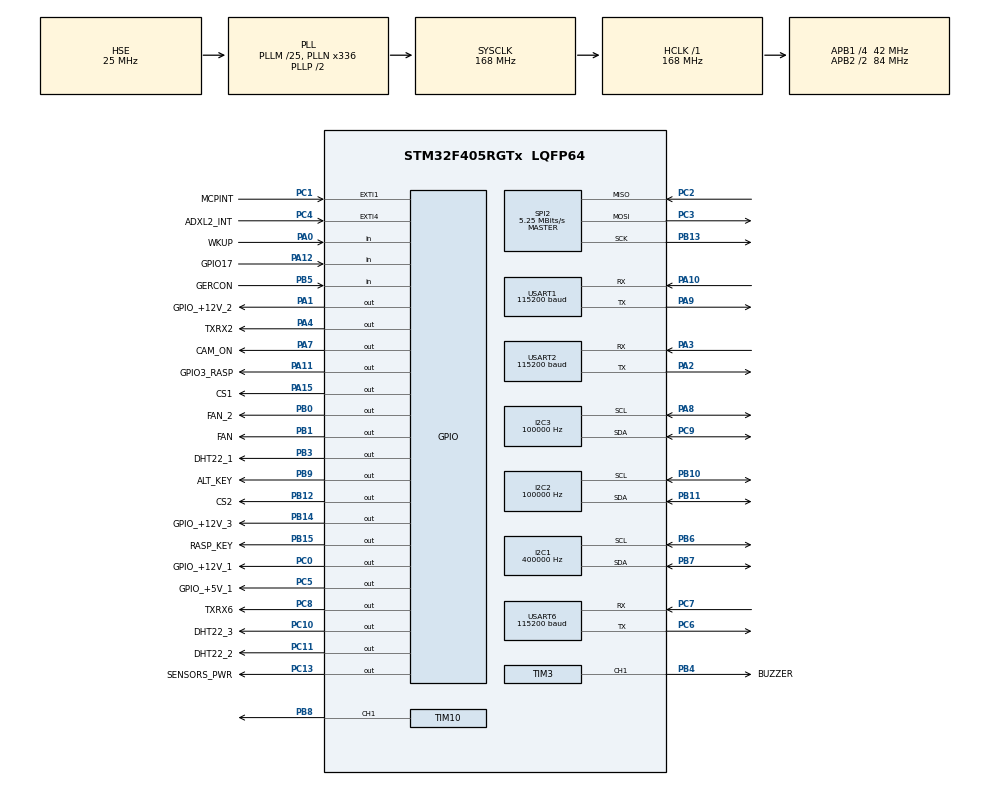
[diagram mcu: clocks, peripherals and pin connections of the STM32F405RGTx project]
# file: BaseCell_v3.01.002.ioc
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Dma.Request0=USART1_RX
Dma.Request1=USART1_TX
Dma.Request2=USART2_RX
Dma.Request3=USART2_TX
Dma.USART1_RX.0.Direction=DMA_PERIPH_TO_MEMORY
Dma.USART1_RX.0.FIFOMode=DMA_FIFOMODE_ENABLE
Dma.USART1_RX.0.FIFOThreshold=DMA_FIFO_THRESHOLD_FULL
Dma.USART1_RX.0.Instance=DMA2_Stream2
Dma.USART1_RX.0.MemBurst=DMA_MBURST_SINGLE
Dma.USART1_RX.0.MemDataAlignment=DMA_MDATAALIGN_BYTE
Dma.USART1_RX.0.MemInc=DMA_MINC_ENABLE
Dma.USART1_RX.0.Mode=DMA_NORMAL
Dma.USART1_RX.0.PeriphBurst=DMA_PBURST_SINGLE
Dma.USART1_RX.0.PeriphDataAlignment=DMA_PDATAALIGN_BYTE
Dma.USART1_RX.0.PeriphInc=DMA_PINC_DISABLE
Dma.USART1_RX.0.Priority=DMA_PRIORITY_LOW
Dma.USART1_TX.1.Direction=DMA_MEMORY_TO_PERIPH
Dma.USART1_TX.1.FIFOMode=DMA_FIFOMODE_ENABLE
Dma.USART1_TX.1.FIFOThreshold=DMA_FIFO_THRESHOLD_FULL
Dma.USART1_TX.1.Instance=DMA2_Stream7
Dma.USART1_TX.1.MemBurst=DMA_MBURST_SINGLE
Dma.USART1_TX.1.MemDataAlignment=DMA_MDATAALIGN_BYTE
Dma.USART1_TX.1.MemInc=DMA_MINC_ENABLE
Dma.USART1_TX.1.Mode=DMA_NORMAL
Dma.USART1_TX.1.PeriphBurst=DMA_PBURST_SINGLE
Dma.USART1_TX.1.PeriphDataAlignment=DMA_PDATAALIGN_BYTE
Dma.USART1_TX.1.PeriphInc=DMA_PINC_DISABLE
Dma.USART1_TX.1.Priority=DMA_PRIORITY_LOW
Dma.USART2_RX.2.Direction=DMA_PERIPH_TO_MEMORY
Dma.USART2_RX.2.FIFOMode=DMA_FIFOMODE_DISABLE
Dma.USART2_RX.2.Instance=DMA1_Stream5
Dma.USART2_RX.2.MemDataAlignment=DMA_MDATAALIGN_BYTE
Dma.USART2_RX.2.MemInc=DMA_MINC_ENABLE
Dma.USART2_RX.2.Mode=DMA_NORMAL
Dma.USART2_RX.2.PeriphDataAlignment=DMA_PDATAALIGN_BYTE
Dma.USART2_RX.2.PeriphInc=DMA_PINC_DISABLE
Dma.USART2_RX.2.Priority=DMA_PRIORITY_MEDIUM
Dma.USART2_TX.3.Direction=DMA_MEMORY_TO_PERIPH
Dma.USART2_TX.3.FIFOMode=DMA_FIFOMODE_ENABLE
Dma.USART2_TX.3.FIFOThreshold=DMA_FIFO_THRESHOLD_FULL
Dma.USART2_TX.3.Instance=DMA1_Stream6
Dma.USART2_TX.3.MemBurst=DMA_MBURST_SINGLE
Dma.USART2_TX.3.MemDataAlignment=DMA_MDATAALIGN_BYTE
Dma.USART2_TX.3.MemInc=DMA_MINC_ENABLE
Dma.USART2_TX.3.Mode=DMA_NORMAL
Dma.USART2_TX.3.PeriphBurst=DMA_PBURST_SINGLE
Dma.USART2_TX.3.PeriphDataAlignment=DMA_PDATAALIGN_BYTE
Dma.USART2_TX.3.PeriphInc=DMA_PINC_DISABLE
Dma.USART2_TX.3.Priority=DMA_PRIORITY_MEDIUM
FREERTOS.HEAP_NUMBER=4
FREERTOS.INCLUDE_eTaskGetState=0
FREERTOS.INCLUDE_pcTaskGetTaskName=0
FREERTOS.INCLUDE_uxTaskGetStackHighWaterMark=0
FREERTOS.INCLUDE_uxTaskPriorityGet=1
FREERTOS.INCLUDE_vTaskCleanUpResources=0
FREERTOS.INCLUDE_vTaskDelay=1
FREERTOS.INCLUDE_vTaskDelayUntil=0
FREERTOS.INCLUDE_vTaskDelete=1
FREERTOS.INCLUDE_vTaskPrioritySet=1
FREERTOS.INCLUDE_vTaskSuspend=1
FREERTOS.INCLUDE_xEventGroupSetBitFromISR=0
FREERTOS.INCLUDE_xQueueGetMutexHolder=0
FREERTOS.INCLUDE_xSemaphoreGetMutexHolder=0
FREERTOS.INCLUDE_xTaskAbortDelay=0
FREERTOS.INCLUDE_xTaskGetCurrentTaskHandle=0
FREERTOS.INCLUDE_xTaskGetHandle=0
FREERTOS.INCLUDE_xTaskResumeFromISR=1
FREERTOS.MEMORY_ALLOCATION=2
FREERTOS.Mutexes01=I2C2Mutex,Dynamic,NULL;spiMutex,Dynamic,NULL
FREERTOS.Queues01=onOffQueue,8,uint16_t,0,Dynamic,NULL,NULL;watchDogQ,4,uint16_t,0,Dynamic,NULL,NULL
FREERTOS.Tasks01=defaultTask,0,256,StartDefaultTask,Default,NULL,Dynamic,NULL,NULL;lightMeter,0,256,lightMeterTask,As weak,NULL,Dynamic,NULL,NULL;accel,0,256,accelTask,Default,NULL,Dynamic,NULL,NULL;tempMeas,0,256,tempMeasTask,Default,NULL,Dynamic,NULL,NULL;uartComm,0,256,uartCommTask,As weak,NULL,Dynamic,NULL,NULL;dimmer,0,256,dimmerTask,As external,NULL,Dynamic,NULL,NULL;canRx,0,256,canRxTask,As external,NULL,Dynamic,NULL,NULL;canTx,0,256,canTxTask,As external,NULL,Dynamic,NULL,NULL
FREERTOS.configCHECK_FOR_STACK_OVERFLOW=0
FREERTOS.configENABLE_BACKWARD_COMPATIBILITY=1
FREERTOS.configGENERATE_RUN_TIME_STATS=1
FREERTOS.configIDLE_SHOULD_YIELD=1
FREERTOS.configLIBRARY_LOWEST_INTERRUPT_PRIORITY=15
FREERTOS.configLIBRARY_MAX_SYSCALL_INTERRUPT_PRIORITY=5
FREERTOS.configMAX_CO_ROUTINE_PRIORITIES=2
FREERTOS.configMAX_PRIORITIES=7
FREERTOS.configMAX_TASK_NAME_LEN=16
FREERTOS.configMINIMAL_STACK_SIZE=128
FREERTOS.configQUEUE_REGISTRY_SIZE=8
FREERTOS.configRECORD_STACK_HIGH_ADDRESS=0
FREERTOS.configTICK_RATE_HZ=1000
FREERTOS.configTOTAL_HEAP_SIZE=32768
FREERTOS.configUSE_APPLICATION_TASK_TAG=0
FREERTOS.configUSE_COUNTING_SEMAPHORES=0
FREERTOS.configUSE_CO_ROUTINES=0
FREERTOS.configUSE_DAEMON_TASK_STARTUP_HOOK=0
FREERTOS.configUSE_IDLE_HOOK=0
FREERTOS.configUSE_MALLOC_FAILED_HOOK=0
FREERTOS.configUSE_MUTEXES=1
FREERTOS.configUSE_NEWLIB_REENTRANT=1
FREERTOS.configUSE_PREEMPTION=1
FREERTOS.configUSE_RECURSIVE_MUTEXES=0
FREERTOS.configUSE_STATS_FORMATTING_FUNCTIONS=1
FREERTOS.configUSE_TASK_NOTIFICATIONS=1
FREERTOS.configUSE_TICKLESS_IDLE=0
FREERTOS.configUSE_TICK_HOOK=0
FREERTOS.configUSE_TIMERS=0
FREERTOS.configUSE_TRACE_FACILITY=1
FREERTOS.copyHeapFile=1
I2C1.AddressingMode=I2C_ADDRESSINGMODE_7BIT
I2C1.ClockSpeed=400000
I2C1.DualAddressMode=I2C_DUALADDRESS_DISABLE
I2C1.GeneralCallMode=I2C_GENERALCALL_DISABLE
I2C1.I2C_Mode=I2C_Fast
I2C1.NoStretchMode=I2C_NOSTRETCH_DISABLE
I2C1.OwnAddress=0
I2C2.AddressingMode=I2C_ADDRESSINGMODE_7BIT
I2C2.ClockSpeed=100000
I2C2.DualAddressMode=I2C_DUALADDRESS_DISABLE
I2C2.GeneralCallMode=I2C_GENERALCALL_DISABLE
I2C2.I2C_Mode=I2C_Standard
I2C2.NoStretchMode=I2C_NOSTRETCH_DISABLE
I2C2.OwnAddress=0
I2C3.AddressingMode=I2C_ADDRESSINGMODE_7BIT
I2C3.ClockSpeed=100000
I2C3.DualAddressMode=I2C_DUALADDRESS_DISABLE
I2C3.GeneralCallMode=I2C_GENERALCALL_DISABLE
I2C3.I2C_Mode=I2C_Standard
I2C3.NoStretchMode=I2C_NOSTRETCH_DISABLE
I2C3.OwnAddress=0
Mcu.Family=STM32F4
Mcu.Name=STM32F405RGTx
Mcu.Package=LQFP64
NVIC.DMA1_Stream5_IRQn=true\:5\:0\:false\:false\:true\:true\:false\:true\:true
NVIC.DMA1_Stream6_IRQn=true\:5\:0\:false\:false\:true\:true\:false\:true\:true
NVIC.DMA2_Stream2_IRQn=true\:5\:0\:false\:false\:true\:true\:false\:true\:true
NVIC.DMA2_Stream7_IRQn=true\:5\:0\:false\:false\:true\:true\:false\:true\:true
NVIC.EXTI1_IRQn=true\:5\:0\:false\:false\:true\:true\:true\:true\:true
NVIC.EXTI4_IRQn=true\:5\:0\:false\:false\:true\:true\:true\:true\:true
NVIC.I2C2_ER_IRQn=true\:5\:0\:false\:false\:true\:true\:true\:true\:true
NVIC.PriorityGroup=NVIC_PRIORITYGROUP_4
NVIC.TIM1_TRG_COM_TIM11_IRQn=true\:5\:0\:false\:false\:true\:true\:true\:true\:true
NVIC.TIM1_UP_TIM10_IRQn=true\:5\:0\:false\:false\:true\:true\:true\:true\:true
NVIC.TIM6_DAC_IRQn=true\:15\:0\:false\:false\:true\:false\:true\:true\:true
NVIC.TIM7_IRQn=true\:5\:0\:false\:false\:true\:true\:true\:true\:true
NVIC.TIM8_TRG_COM_TIM14_IRQn=true\:5\:0\:false\:false\:true\:true\:true\:true\:true
NVIC.TIM8_UP_TIM13_IRQn=true\:5\:0\:false\:false\:true\:true\:true\:true\:true
NVIC.TimeBase=TIM6_DAC_IRQn
NVIC.TimeBaseIP=TIM6
NVIC.USART1_IRQn=true\:5\:0\:false\:false\:true\:true\:true\:true\:true
NVIC.USART2_IRQn=true\:5\:0\:false\:false\:true\:true\:true\:true\:true
NVIC.USART6_IRQn=true\:5\:0\:false\:false\:true\:true\:true\:true\:true
PA0-WKUP.GPIO_Label=WKUP
PA0-WKUP.Signal=GPIO_Input
PA1.GPIO_Label=GPIO_+12V_2
PA1.Signal=GPIO_Output
PA10.Mode=Asynchronous
PA10.Signal=USART1_RX
PA11.GPIO_Label=GPIO3_RASP
PA11.PinState=GPIO_PIN_SET
PA11.Signal=GPIO_Output
PA12.GPIO_Label=GPIO17
PA12.Signal=GPIO_Input
PA13.Mode=Serial_Wire
PA13.Signal=SYS_JTMS-SWDIO
PA14.Mode=Serial_Wire
PA14.Signal=SYS_JTCK-SWCLK
PA15.GPIO_Label=CS1
PA15.GPIO_Speed=GPIO_SPEED_FREQ_VERY_HIGH
PA15.PinState=GPIO_PIN_SET
PA15.Signal=GPIO_Output
PA2.Mode=Asynchronous
PA2.Signal=USART2_TX
PA3.Mode=Asynchronous
PA3.Signal=USART2_RX
PA4.GPIO_Label=TXRX2
PA4.Signal=GPIO_Output
PA7.GPIO_Label=CAM_ON
PA7.Signal=GPIO_Output
PA8.GPIO_Pu=GPIO_PULLUP
PA8.Mode=I2C
PA8.Signal=I2C3_SCL
PA9.Mode=Asynchronous
PA9.Signal=USART1_TX
PB0.GPIO_Label=FAN_2
PB0.Signal=GPIO_Output
PB1.GPIO_Label=FAN
PB1.Signal=GPIO_Output
PB10.GPIO_Pu=GPIO_PULLUP
PB10.Mode=I2C
PB10.Signal=I2C2_SCL
PB11.GPIO_Pu=GPIO_PULLUP
PB11.Mode=I2C
PB11.Signal=I2C2_SDA
PB12.GPIO_Label=CS2
PB12.GPIO_Speed=GPIO_SPEED_FREQ_VERY_HIGH
PB12.PinState=GPIO_PIN_SET
PB12.Signal=GPIO_Output
PB13.Mode=Full_Duplex_Master
PB13.Signal=SPI2_SCK
PB14.GPIO_Label=GPIO_+12V_3
PB14.Signal=GPIO_Output
PB15.GPIO_Label=RASP_KEY
PB15.Signal=GPIO_Output
PB3.GPIO_Label=DHT22_1
PB3.Signal=GPIO_Output
PB4.GPIO_Label=BUZZER
PB4.GPIO_Speed=GPIO_SPEED_FREQ_HIGH
PB4.Signal=S_TIM3_CH1
PB5.GPIO_Label=GERCON
PB5.Signal=GPIO_Input
PB6.GPIO_Pu=GPIO_PULLUP
PB6.Mode=I2C
PB6.Signal=I2C1_SCL
PB7.GPIO_Pu=GPIO_PULLUP
PB7.Mode=I2C
PB7.Signal=I2C1_SDA
PB8.Signal=S_TIM10_CH1
PB9.GPIO_Label=ALT_KEY
PB9.Signal=GPIO_Output
PC0.GPIO_Label=GPIO_+12V_1
PC0.Signal=GPIO_Output
PC1.GPIO_Label=MCPINT
PC1.GPIO_ModeDefaultEXTI=GPIO_MODE_IT_FALLING
PC1.GPIO_PuPd=GPIO_PULLUP
PC1.Signal=GPXTI1
PC10.GPIO_Label=DHT22_3
PC10.Signal=GPIO_Output
PC11.GPIO_Label=DHT22_2
PC11.Signal=GPIO_Output
PC13-ANTI_TAMP.GPIO_Label=SENSORS_PWR
PC13-ANTI_TAMP.Signal=GPIO_Output
PC2.Mode=Full_Duplex_Master
PC2.Signal=SPI2_MISO
PC3.Mode=Full_Duplex_Master
PC3.Signal=SPI2_MOSI
PC4.GPIO_Label=ADXL2_INT
PC4.Signal=GPXTI4
PC5.GPIO_Label=GPIO_+5V_1
PC5.Signal=GPIO_Output
PC6.Mode=Asynchronous
PC6.Signal=USART6_TX
PC7.Mode=Asynchronous
PC7.Signal=USART6_RX
PC8.GPIO_Label=TXRX6
PC8.Signal=GPIO_Output
PC9.GPIO_Pu=GPIO_PULLUP
PC9.Mode=I2C
PC9.Signal=I2C3_SDA
PH0-OSC_IN.Mode=HSE-External-Oscillator
PH0-OSC_IN.Signal=RCC_OSC_IN
PH1-OSC_OUT.Mode=HSE-External-Oscillator
PH1-OSC_OUT.Signal=RCC_OSC_OUT
ProjectManager.HeapSize=0x2000
ProjectManager.StackSize=0x4000
ProjectManager.TargetToolchain=STM32CubeIDE
RCC.48MHZClocksFreq_Value=84000000
RCC.AHBFreq_Value=168000000
RCC.APB1CLKDivider=RCC_HCLK_DIV4
RCC.APB1Freq_Value=42000000
RCC.APB1TimFreq_Value=84000000
RCC.APB2CLKDivider=RCC_HCLK_DIV2
RCC.APB2Freq_Value=84000000
RCC.APB2TimFreq_Value=168000000
RCC.CortexFreq_Value=168000000
RCC.FLatency=FLASH_LATENCY_5
RCC.HCLKFreq_Value=168000000
RCC.HSE_VALUE=25000000
RCC.HSI_VALUE=16000000
RCC.LSE_VALUE=32768
RCC.PLLM=25
RCC.PLLN=336
RCC.PLLSourceVirtual=RCC_PLLSOURCE_HSE
RCC.SYSCLKFreq_VALUE=168000000
RCC.SYSCLKSource=RCC_SYSCLKSOURCE_PLLCLK
RCC.VCOOutputFreq_Value=336000000
SH.S_TIM10_CH1.0=TIM10_CH1,PWM Generation1 CH1
SH.S_TIM3_CH1.0=TIM3_CH1,PWM Generation1 CH1
SPI2.BaudRatePrescaler=SPI_BAUDRATEPRESCALER_8
SPI2.CalculateBaudRate=5.25 MBits/s
SPI2.Direction=SPI_DIRECTION_2LINES
SPI2.Mode=SPI_MODE_MASTER
SPI2.VirtualType=VM_MASTER
TIM10.Channel=TIM_CHANNEL_1
TIM10.Period=999
TIM10.Prescaler=167
TIM11.AutoReloadPreload=TIM_AUTORELOAD_PRELOAD_DISABLE
TIM11.ClockDivision=TIM_CLOCKDIVISION_DIV1
TIM11.CounterMode=TIM_COUNTERMODE_UP
TIM11.Period=999
TIM11.Prescaler=167
TIM13.Period=19999
TIM13.Prescaler=167
TIM14.Period=99
TIM14.Prescaler=83
TIM3.AutoReloadPreload=TIM_AUTORELOAD_PRELOAD_DISABLE
TIM3.Channel-PWM\ Generation1\ CH1=TIM_CHANNEL_1
TIM3.ClockDivision=TIM_CLOCKDIVISION_DIV1
TIM3.CounterMode=TIM_COUNTERMODE_UP
TIM3.OC1Preload_PWM=ENABLE
TIM3.OCFastMode_PWM-PWM\ Generation1\ CH1=TIM_OCFAST_DISABLE
TIM3.OCMode_PWM-PWM\ Generation1\ CH1=TIM_OCMODE_PWM1
TIM3.OCPolarity_1=TIM_OCPOLARITY_HIGH
TIM3.Period=499
TIM3.Prescaler=83
TIM3.Pulse-PWM\ Generation1\ CH1=124
TIM3.TIM_MasterOutputTrigger=TIM_TRGO_RESET
TIM3.TIM_MasterSlaveMode=TIM_MASTERSLAVEMODE_DISABLE
TIM7.AutoReloadPreload=TIM_AUTORELOAD_PRELOAD_DISABLE
TIM7.CounterMode=TIM_COUNTERMODE_UP
TIM7.Period=65535
TIM7.Prescaler=16799
TIM7.TIM_MasterOutputTrigger=TIM_TRGO_RESET
TIM8.Period=1999
TIM8.Prescaler=16799
USART1.BaudRate=115200
USART1.Mode=MODE_TX_RX
USART1.OverSampling=UART_OVERSAMPLING_16
USART1.Parity=PARITY_NONE
USART1.StopBits=STOPBITS_1
USART1.VirtualMode=VM_ASYNC
USART1.WordLength=WORDLENGTH_8B
USART2.BaudRate=115200
USART2.Mode=MODE_TX_RX
USART2.OverSampling=UART_OVERSAMPLING_16
USART2.Parity=PARITY_NONE
USART2.StopBits=STOPBITS_1
USART2.VirtualMode=VM_ASYNC
USART2.WordLength=WORDLENGTH_8B
USART6.BaudRate=115200
USART6.Mode=MODE_TX_RX
USART6.OverSampling=UART_OVERSAMPLING_16
USART6.Parity=PARITY_NONE
USART6.StopBits=STOPBITS_1
USART6.VirtualMode=VM_ASYNC
USART6.WordLength=WORDLENGTH_8B
VP_FREERTOS_VS_CMSIS_V1.Mode=CMSIS_V1
VP_SYS_VS_tim6.Mode=TIM6
VP_TIM10_VS_ClockSourceINT.Mode=Enable_Timer
VP_TIM11_VS_ClockSourceINT.Mode=Enable_Timer
VP_TIM13_VS_ClockSourceINT.Mode=Enable_Timer
VP_TIM14_VS_ClockSourceINT.Mode=Enable_Timer
VP_TIM3_VS_ClockSourceINT.Mode=Internal
VP_TIM7_VS_ClockSourceINT.Mode=Enable_Timer
VP_TIM8_VS_ClockSourceINT.Mode=Internal
board=custom

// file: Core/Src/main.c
/* USER CODE BEGIN Header */
/**
  ******************************************************************************
  * @file           : main.c
  * @brief          : Main program body
  ******************************************************************************
  * @attention
  *
  * <h2><center>&copy; Copyright (c) 2021 STMicroelectronics.
  * All rights reserved.</center></h2>
  *
  * This software component is licensed by ST under Ultimate Liberty license
  * SLA0044, the "License"; You may not use this file except in compliance with
  * the License. You may obtain a copy of the License at:
  *                             www.st.com/SLA0044
  *
  ******************************************************************************
  */
/* USER CODE END Header */
#include "main.h"
#include "cmsis_os.h"

/* USER CODE BEGIN Includes */
#include "stm32f4xx_hal.h"
#include "string.h"
#include "adxl345.h"
#include "tla2024.h"
#include "dht22.h"
#include "apds9960.h"
#include "usart.h"
#include "utilites.h"
#include "eeprom.h"
#include "dimmer.h"
#include "CANSPI.h"
/* USER CODE END Includes */

/* USER CODE BEGIN PD */
#define CV_EXT_INTERRUPT_ID 	0x05
#define TIM11_DELAY_ID			0x06

#define RASP_OFF_COUNTER		500
#define RASP_SHTDN_DELAY		45000

#define TEMPERATURE				400
#define TEMP_HYSTERESE			20
#define TEMP_SENS_NORM			1
#define TEMP_SENSOR_FAIL		0
/* USER CODE END PD */

 I2C_HandleTypeDef hi2c1;
I2C_HandleTypeDef hi2c2;
I2C_HandleTypeDef hi2c3;

SPI_HandleTypeDef hspi2;

TIM_HandleTypeDef htim3;
TIM_HandleTypeDef htim7;
TIM_HandleTypeDef htim8;
TIM_HandleTypeDef htim10;
TIM_HandleTypeDef htim11;
TIM_HandleTypeDef htim13;
TIM_HandleTypeDef htim14;

UART_HandleTypeDef huart1;
UART_HandleTypeDef huart2;
UART_HandleTypeDef huart6;
DMA_HandleTypeDef hdma_usart1_rx;
DMA_HandleTypeDef hdma_usart1_tx;
DMA_HandleTypeDef hdma_usart2_rx;
DMA_HandleTypeDef hdma_usart2_tx;

osThreadId defaultTaskHandle;
osThreadId lightMeterHandle;
osThreadId accelHandle;
osThreadId tempMeasHandle;
osThreadId uartCommHandle;
osThreadId dimmerHandle;
osThreadId canRxHandle;
osThreadId canTxHandle;
osMessageQId onOffQueueHandle;
osMessageQId watchDogQHandle;
osMutexId I2C2MutexHandle;
osMutexId spiMutexHandle;
/* USER CODE BEGIN PV */

QueueHandle_t qSensorsHandle;
uint8_t qSensorsBuffer[ MAIL_SIZE * sizeof( sensorsData ) ];
StaticQueue_t qSensorsQueueBuffer;

uint16_t tickCounter = 0;
uint8_t currentVoltageRxBuf [CV_RX_BUF_SIZE];
uint8_t raspRxBuf [RASP_RX_BUF_SIZE];
uint8_t fanAutoFlag = 0;
int16_t accelX = 0;
int16_t accelY = 0;
int16_t accelZ = 0;

uint8_t intSource = 0;
float Xresult;
float Yresult;
float Zresult;

uint8_t shutdownFlag = 0;
uint32_t shutdownCounter = 0;
uint16_t gerconCounter = 0;
uint16_t cvRequestCounter = 0;
uint8_t gerconState = 0;

uint32_t raspOffCounter = 0;
uint16_t stateChangeCounter = 0;
uint8_t raspOffState = 0;

uint16_t wakeUpPinCounter = 0;
uint8_t wakeUpFlag = 0;

uint32_t secondCounter = 0;

uint16_t pulseDuration = 0;
const uint8_t cvTimeoutResponse[8] = {0xAA, 0x0F, 0x08, 0x11, 0x01, 0, 0, 0x55};

extern uint8_t engineSwitchFlag;
extern uint16_t onBoardVoltage;
extern uint8_t engineState;
extern uint8_t misStatusByte0;
extern uint8_t misStatusByte1;
extern uint8_t cvStatusByteExtern;
extern uint8_t breaksStateTelem;
extern uint8_t queueStatusByte;
extern uint8_t queueStatusByte1;
extern uint8_t cmdTempBuf[16];
//extern UBaseType_t mailInQueue;

extern uint8_t destTempBuf[16];

uint16_t VirtAddVarTab[NB_OF_VAR];
uint8_t tempSensorState = 0;
uint8_t tempSensorState1 = 0;
uint8_t sensorsOnFlag = 1;

volatile unsigned long ulHighFrequencyTimerTicks;

int16_t debugTemp0;
int16_t debugTemp1;
int16_t debugTemp2;

__IO int32_t osMailFreeCounter = 0;
__IO uint32_t queueErrorCnt = 0;

static volatile sensorsData xSensor, xSensor1;
static volatile sensorsData *sensor = &xSensor;
static volatile sensorsData *sensor1 = &xSensor1;

uint8_t resetFlag = 0;
uint8_t gpio17State = 0;
uint8_t turnOffBreaksFlag = 0;

volatile uint8_t timeOutFlag = 0;
volatile uint32_t timeoutCnt = 0;
volatile uint8_t raspRestartFlag = 0;

static volatile uint8_t cvCounter = 0;
uint32_t timeOutCounter = 0;
uint32_t uartErrorCounter = 0;

float pwmValue;
uint16_t pwm_Value;
uint16_t targetValue;
BH1750_device_t* monitor;
uint32_t i2c2ErrorCode = 0;
/* USER CODE END PV */

void SystemClock_Config(void);
static void MX_GPIO_Init(void);
static void MX_DMA_Init(void);
static void MX_I2C1_Init(void);
static void MX_I2C2_Init(void);
static void MX_I2C3_Init(void);
static void MX_TIM3_Init(void);
static void MX_USART1_UART_Init(void);
static void MX_USART2_UART_Init(void);
static void MX_USART6_UART_Init(void);
static void MX_TIM7_Init(void);
static void MX_TIM11_Init(void);
static void MX_TIM13_Init(void);
static void MX_TIM14_Init(void);
static void MX_TIM10_Init(void);
static void MX_TIM8_Init(void);
static void MX_SPI2_Init(void);
void StartDefaultTask(void const * argument);
void lightMeterTask(void const * argument);
void accelTask(void const * argument);
void tempMeasTask(void const * argument);
void uartCommTask(void const * argument);
extern void dimmerTask(void const * argument);
extern void canRxTask(void const * argument);
extern void canTxTask(void const * argument);

int main(void)
{

  /* MCU Configuration--------------------------------------------------------*/

  /* Reset of all peripherals, Initializes the Flash interface and the Systick. */
  HAL_Init();

  /* Configure the system clock */
  SystemClock_Config();

  /* Initialize all configured peripherals */
  MX_GPIO_Init();
  MX_DMA_Init();
  MX_I2C1_Init();
  MX_I2C2_Init();
  MX_I2C3_Init();
  MX_TIM3_Init();
  MX_USART1_UART_Init();
  MX_USART2_UART_Init();
  MX_USART6_UART_Init();
  MX_TIM7_Init();
  MX_TIM11_Init();
  MX_TIM13_Init();
  MX_TIM14_Init();
  MX_TIM10_Init();
  MX_TIM8_Init();
  MX_SPI2_Init();
  /* USER CODE BEGIN 2 */
  HAL_GPIO_WritePin(TXRX6_GPIO_Port, TXRX6_Pin, RESET);

  HAL_GPIO_WritePin(SENSORS_PWR_GPIO_Port, SENSORS_PWR_Pin, SET);

  HAL_TIM_Base_Start_IT(&htim11);

	TLA2024_Init();
	HAL_TIM_Base_Stop_IT(&htim13);
	HAL_TIM_Base_Stop_IT(&htim10);
	monitor = BH1750_init_dev_struct(&hi2c3, "monitor", true);
	BH1750_init_dev(monitor);
	HAL_TIM_PWM_Start(&htim10, TIM_CHANNEL_1);

  /* USER CODE END 2 */

  /* Create the mutex(es) */
  /* definition and creation of I2C2Mutex */
  osMutexDef(I2C2Mutex);
  I2C2MutexHandle = osMutexCreate(osMutex(I2C2Mutex));

  /* definition and creation of spiMutex */
  osMutexDef(spiMutex);
  spiMutexHandle = osMutexCreate(osMutex(spiMutex));

  /* Create the queue(s) */
  /* definition and creation of onOffQueue */
  osMessageQDef(onOffQueue, 8, uint16_t);
  onOffQueueHandle = osMessageCreate(osMessageQ(onOffQueue), NULL);

  /* definition and creation of watchDogQ */
  osMessageQDef(watchDogQ, 4, uint16_t);
  watchDogQHandle = osMessageCreate(osMessageQ(watchDogQ), NULL);

  /* USER CODE BEGIN RTOS_QUEUES */
  /* add queues, ... */
  qSensorsHandle = xQueueCreateStatic(MAIL_SIZE, sizeof (sensorsData), &qSensorsBuffer[0], &qSensorsQueueBuffer);

  /* USER CODE END RTOS_QUEUES */

  /* Create the thread(s) */
  /* definition and creation of defaultTask */
  osThreadDef(defaultTask, StartDefaultTask, osPriorityNormal, 0, 256);
  defaultTaskHandle = osThreadCreate(osThread(defaultTask), NULL);

  /* definition and creation of lightMeter */
  osThreadDef(lightMeter, lightMeterTask, osPriorityNormal, 0, 256);
  lightMeterHandle = osThreadCreate(osThread(lightMeter), NULL);

  /* definition and creation of accel */
  osThreadDef(accel, accelTask, osPriorityNormal, 0, 256);
  accelHandle = osThreadCreate(osThread(accel), NULL);

  /* definition and creation of tempMeas */
  osThreadDef(tempMeas, tempMeasTask, osPriorityNormal, 0, 256);
  tempMeasHandle = osThreadCreate(osThread(tempMeas), NULL);

  /* definition and creation of uartComm */
  osThreadDef(uartComm, uartCommTask, osPriorityNormal, 0, 256);
  uartCommHandle = osThreadCreate(osThread(uartComm), NULL);

  /* definition and creation of dimmer */
  osThreadDef(dimmer, dimmerTask, osPriorityNormal, 0, 256);
  dimmerHandle = osThreadCreate(osThread(dimmer), NULL);

  /* definition and creation of canRx */
  osThreadDef(canRx, canRxTask, osPriorityNormal, 0, 256);
  canRxHandle = osThreadCreate(osThread(canRx), NULL);

  /* definition and creation of canTx */
  osThreadDef(canTx, canTxTask, osPriorityNormal, 0, 256);
  canTxHandle = osThreadCreate(osThread(canTx), NULL);

  /* Start scheduler */
  osKernelStart();

  /* We should never get here as control is now taken by the scheduler */
  /* Infinite loop */
  while (1)
  {

  }
}

void SystemClock_Config(void)
{
  RCC_OscInitTypeDef RCC_OscInitStruct = {0};
  RCC_ClkInitTypeDef RCC_ClkInitStruct = {0};

  /** Configure the main internal regulator output voltage
  */
  __HAL_RCC_PWR_CLK_ENABLE();
  __HAL_PWR_VOLTAGESCALING_CONFIG(PWR_REGULATOR_VOLTAGE_SCALE1);

  /** Initializes the RCC Oscillators according to the specified parameters
  * in the RCC_OscInitTypeDef structure.
  */
  RCC_OscInitStruct.OscillatorType = RCC_OSCILLATORTYPE_HSE;
  RCC_OscInitStruct.HSEState = RCC_HSE_ON;
  RCC_OscInitStruct.PLL.PLLState = RCC_PLL_ON;
  RCC_OscInitStruct.PLL.PLLSource = RCC_PLLSOURCE_HSE;
  RCC_OscInitStruct.PLL.PLLM = 25;
  RCC_OscInitStruct.PLL.PLLN = 336;
  RCC_OscInitStruct.PLL.PLLP = RCC_PLLP_DIV2;
  RCC_OscInitStruct.PLL.PLLQ = 4;
  if (HAL_RCC_OscConfig(&RCC_OscInitStruct) != HAL_OK)
  {
    Error_Handler();
  }

  /** Initializes the CPU, AHB and APB buses clocks
  */
  RCC_ClkInitStruct.ClockType = RCC_CLOCKTYPE_HCLK|RCC_CLOCKTYPE_SYSCLK
                              |RCC_CLOCKTYPE_PCLK1|RCC_CLOCKTYPE_PCLK2;
  RCC_ClkInitStruct.SYSCLKSource = RCC_SYSCLKSOURCE_PLLCLK;
  RCC_ClkInitStruct.AHBCLKDivider = RCC_SYSCLK_DIV1;
  RCC_ClkInitStruct.APB1CLKDivider = RCC_HCLK_DIV4;
  RCC_ClkInitStruct.APB2CLKDivider = RCC_HCLK_DIV2;

  if (HAL_RCC_ClockConfig(&RCC_ClkInitStruct, FLASH_LATENCY_5) != HAL_OK)
  {
    Error_Handler();
  }
}

static void MX_I2C1_Init(void)
{

  hi2c1.Instance = I2C1;
  hi2c1.Init.ClockSpeed = 400000;
  hi2c1.Init.DutyCycle = I2C_DUTYCYCLE_2;
  hi2c1.Init.OwnAddress1 = 0;
  hi2c1.Init.AddressingMode = I2C_ADDRESSINGMODE_7BIT;
  hi2c1.Init.DualAddressMode = I2C_DUALADDRESS_DISABLE;
  hi2c1.Init.OwnAddress2 = 0;
  hi2c1.Init.GeneralCallMode = I2C_GENERALCALL_DISABLE;
  hi2c1.Init.NoStretchMode = I2C_NOSTRETCH_DISABLE;
  if (HAL_I2C_Init(&hi2c1) != HAL_OK)
  {
    Error_Handler();
  }

}

static void MX_I2C2_Init(void)
{

  hi2c2.Instance = I2C2;
  hi2c2.Init.ClockSpeed = 100000;
  hi2c2.Init.DutyCycle = I2C_DUTYCYCLE_2;
  hi2c2.Init.OwnAddress1 = 0;
  hi2c2.Init.AddressingMode = I2C_ADDRESSINGMODE_7BIT;
  hi2c2.Init.DualAddressMode = I2C_DUALADDRESS_DISABLE;
  hi2c2.Init.OwnAddress2 = 0;
  hi2c2.Init.GeneralCallMode = I2C_GENERALCALL_DISABLE;
  hi2c2.Init.NoStretchMode = I2C_NOSTRETCH_DISABLE;
  if (HAL_I2C_Init(&hi2c2) != HAL_OK)
  {
    Error_Handler();
  }

}

static void MX_I2C3_Init(void)
{

  hi2c3.Instance = I2C3;
  hi2c3.Init.ClockSpeed = 100000;
  hi2c3.Init.DutyCycle = I2C_DUTYCYCLE_2;
  hi2c3.Init.OwnAddress1 = 0;
  hi2c3.Init.AddressingMode = I2C_ADDRESSINGMODE_7BIT;
  hi2c3.Init.DualAddressMode = I2C_DUALADDRESS_DISABLE;
  hi2c3.Init.OwnAddress2 = 0;
  hi2c3.Init.GeneralCallMode = I2C_GENERALCALL_DISABLE;
  hi2c3.Init.NoStretchMode = I2C_NOSTRETCH_DISABLE;
  if (HAL_I2C_Init(&hi2c3) != HAL_OK)
  {
    Error_Handler();
  }

}

static void MX_SPI2_Init(void)
{

  /* SPI2 parameter configuration*/
  hspi2.Instance = SPI2;
  hspi2.Init.Mode = SPI_MODE_MASTER;
  hspi2.Init.Direction = SPI_DIRECTION_2LINES;
  hspi2.Init.DataSize = SPI_DATASIZE_8BIT;
  hspi2.Init.CLKPolarity = SPI_POLARITY_LOW;
  hspi2.Init.CLKPhase = SPI_PHASE_1EDGE;
  hspi2.Init.NSS = SPI_NSS_SOFT;
  hspi2.Init.BaudRatePrescaler = SPI_BAUDRATEPRESCALER_8;
  hspi2.Init.FirstBit = SPI_FIRSTBIT_MSB;
  hspi2.Init.TIMode = SPI_TIMODE_DISABLE;
  hspi2.Init.CRCCalculation = SPI_CRCCALCULATION_DISABLE;
  hspi2.Init.CRCPolynomial = 10;
  if (HAL_SPI_Init(&hspi2) != HAL_OK)
  {
    Error_Handler();
  }

}

static void MX_TIM3_Init(void)
{

  TIM_ClockConfigTypeDef sClockSourceConfig = {0};
  TIM_MasterConfigTypeDef sMasterConfig = {0};
  TIM_OC_InitTypeDef sConfigOC = {0};

  htim3.Instance = TIM3;
  htim3.Init.Prescaler = 83;
  htim3.Init.CounterMode = TIM_COUNTERMODE_UP;
  htim3.Init.Period = 499;
  htim3.Init.ClockDivision = TIM_CLOCKDIVISION_DIV1;
  htim3.Init.AutoReloadPreload = TIM_AUTORELOAD_PRELOAD_DISABLE;
  if (HAL_TIM_Base_Init(&htim3) != HAL_OK)
  {
    Error_Handler();
  }
  sClockSourceConfig.ClockSource = TIM_CLOCKSOURCE_INTERNAL;
  if (HAL_TIM_ConfigClockSource(&htim3, &sClockSourceConfig) != HAL_OK)
  {
    Error_Handler();
  }
  if (HAL_TIM_PWM_Init(&htim3) != HAL_OK)
  {
    Error_Handler();
  }
  sMasterConfig.MasterOutputTrigger = TIM_TRGO_RESET;
  sMasterConfig.MasterSlaveMode = TIM_MASTERSLAVEMODE_DISABLE;
  if (HAL_TIMEx_MasterConfigSynchronization(&htim3, &sMasterConfig) != HAL_OK)
  {
    Error_Handler();
  }
  sConfigOC.OCMode = TIM_OCMODE_PWM1;
  sConfigOC.Pulse = 124;
  sConfigOC.OCPolarity = TIM_OCPOLARITY_HIGH;
  sConfigOC.OCFastMode = TIM_OCFAST_DISABLE;
  if (HAL_TIM_PWM_ConfigChannel(&htim3, &sConfigOC, TIM_CHANNEL_1) != HAL_OK)
  {
    Error_Handler();
  }
  HAL_TIM_MspPostInit(&htim3);

}

static void MX_TIM7_Init(void)
{

  TIM_MasterConfigTypeDef sMasterConfig = {0};

  htim7.Instance = TIM7;
  htim7.Init.Prescaler = 16799;
  htim7.Init.CounterMode = TIM_COUNTERMODE_UP;
  htim7.Init.Period = 65535;
  htim7.Init.AutoReloadPreload = TIM_AUTORELOAD_PRELOAD_DISABLE;
  if (HAL_TIM_Base_Init(&htim7) != HAL_OK)
  {
    Error_Handler();
  }
  sMasterConfig.MasterOutputTrigger = TIM_TRGO_RESET;
  sMasterConfig.MasterSlaveMode = TIM_MASTERSLAVEMODE_DISABLE;
  if (HAL_TIMEx_MasterConfigSynchronization(&htim7, &sMasterConfig) != HAL_OK)
  {
    Error_Handler();
  }

}

static void MX_TIM8_Init(void)
{

  TIM_ClockConfigTypeDef sClockSourceConfig = {0};
  TIM_MasterConfigTypeDef sMasterConfig = {0};

  htim8.Instance = TIM8;
  htim8.Init.Prescaler = 16799;
  htim8.Init.CounterMode = TIM_COUNTERMODE_UP;
  htim8.Init.Period = 1999;
  htim8.Init.ClockDivision = TIM_CLOCKDIVISION_DIV1;
  htim8.Init.RepetitionCounter = 0;
  htim8.Init.AutoReloadPreload = TIM_AUTORELOAD_PRELOAD_DISABLE;
  if (HAL_TIM_Base_Init(&htim8) != HAL_OK)
  {
    Error_Handler();
  }
  sClockSourceConfig.ClockSource = TIM_CLOCKSOURCE_INTERNAL;
  if (HAL_TIM_ConfigClockSource(&htim8, &sClockSourceConfig) != HAL_OK)
  {
    Error_Handler();
  }
  sMasterConfig.MasterOutputTrigger = TIM_TRGO_RESET;
  sMasterConfig.MasterSlaveMode = TIM_MASTERSLAVEMODE_DISABLE;
  if (HAL_TIMEx_MasterConfigSynchronization(&htim8, &sMasterConfig) != HAL_OK)
  {
    Error_Handler();
  }

}

static void MX_TIM10_Init(void)
{

  TIM_OC_InitTypeDef sConfigOC = {0};

  htim10.Instance = TIM10;
  htim10.Init.Prescaler = 167;
  htim10.Init.CounterMode = TIM_COUNTERMODE_UP;
  htim10.Init.Period = 999;
  htim10.Init.ClockDivision = TIM_CLOCKDIVISION_DIV1;
  htim10.Init.AutoReloadPreload = TIM_AUTORELOAD_PRELOAD_DISABLE;
  if (HAL_TIM_Base_Init(&htim10) != HAL_OK)
  {
    Error_Handler();
  }
  if (HAL_TIM_PWM_Init(&htim10) != HAL_OK)
  {
    Error_Handler();
  }
  sConfigOC.OCMode = TIM_OCMODE_PWM1;
  sConfigOC.Pulse = 0;
  sConfigOC.OCPolarity = TIM_OCPOLARITY_HIGH;
  sConfigOC.OCFastMode = TIM_OCFAST_DISABLE;
  if (HAL_TIM_PWM_ConfigChannel(&htim10, &sConfigOC, TIM_CHANNEL_1) != HAL_OK)
  {
    Error_Handler();
  }
  HAL_TIM_MspPostInit(&htim10);

}

static void MX_TIM11_Init(void)
{

  htim11.Instance = TIM11;
  htim11.Init.Prescaler = 167;
  htim11.Init.CounterMode = TIM_COUNTERMODE_UP;
  htim11.Init.Period = 999;
  htim11.Init.ClockDivision = TIM_CLOCKDIVISION_DIV1;
  htim11.Init.AutoReloadPreload = TIM_AUTORELOAD_PRELOAD_DISABLE;
  if (HAL_TIM_Base_Init(&htim11) != HAL_OK)
  {
    Error_Handler();
  }

}

static void MX_TIM13_Init(void)
{

  htim13.Instance = TIM13;
  htim13.Init.Prescaler = 167;
  htim13.Init.CounterMode = TIM_COUNTERMODE_UP;
  htim13.Init.Period = 19999;
  htim13.Init.ClockDivision = TIM_CLOCKDIVISION_DIV1;
  htim13.Init.AutoReloadPreload = TIM_AUTORELOAD_PRELOAD_DISABLE;
  if (HAL_TIM_Base_Init(&htim13) != HAL_OK)
  {
    Error_Handler();
  }

}

static void MX_TIM14_Init(void)
{

  htim14.Instance = TIM14;
  htim14.Init.Prescaler = 83;
  htim14.Init.CounterMode = TIM_COUNTERMODE_UP;
  htim14.Init.Period = 99;
  htim14.Init.ClockDivision = TIM_CLOCKDIVISION_DIV1;
  htim14.Init.AutoReloadPreload = TIM_AUTORELOAD_PRELOAD_DISABLE;
  if (HAL_TIM_Base_Init(&htim14) != HAL_OK)
  {
    Error_Handler();
  }

}

static void MX_USART1_UART_Init(void)
{

  huart1.Instance = USART1;
  huart1.Init.BaudRate = 115200;
  huart1.Init.WordLength = UART_WORDLENGTH_8B;
  huart1.Init.StopBits = UART_STOPBITS_1;
  huart1.Init.Parity = UART_PARITY_NONE;
  huart1.Init.Mode = UART_MODE_TX_RX;
  huart1.Init.HwFlowCtl = UART_HWCONTROL_NONE;
  huart1.Init.OverSampling = UART_OVERSAMPLING_16;
  if (HAL_UART_Init(&huart1) != HAL_OK)
  {
    Error_Handler();
  }

}

static void MX_USART2_UART_Init(void)
{

  huart2.Instance = USART2;
  huart2.Init.BaudRate = 115200;
  huart2.Init.WordLength = UART_WORDLENGTH_8B;
  huart2.Init.StopBits = UART_STOPBITS_1;
  huart2.Init.Parity = UART_PARITY_NONE;
  huart2.Init.Mode = UART_MODE_TX_RX;
  huart2.Init.HwFlowCtl = UART_HWCONTROL_NONE;
  huart2.Init.OverSampling = UART_OVERSAMPLING_16;
  if (HAL_UART_Init(&huart2) != HAL_OK)
  {
    Error_Handler();
  }

}

static void MX_USART6_UART_Init(void)
{

  huart6.Instance = USART6;
  huart6.Init.BaudRate = 115200;
  huart6.Init.WordLength = UART_WORDLENGTH_8B;
  huart6.Init.StopBits = UART_STOPBITS_1;
  huart6.Init.Parity = UART_PARITY_NONE;
  huart6.Init.Mode = UART_MODE_TX_RX;
  huart6.Init.HwFlowCtl = UART_HWCONTROL_NONE;
  huart6.Init.OverSampling = UART_OVERSAMPLING_16;
  if (HAL_UART_Init(&huart6) != HAL_OK)
  {
    Error_Handler();
  }

}

static void MX_DMA_Init(void)
{

  /* DMA controller clock enable */
  __HAL_RCC_DMA2_CLK_ENABLE();
  __HAL_RCC_DMA1_CLK_ENABLE();

  /* DMA interrupt init */
  /* DMA1_Stream5_IRQn interrupt configuration */
  HAL_NVIC_SetPriority(DMA1_Stream5_IRQn, 5, 0);
  HAL_NVIC_EnableIRQ(DMA1_Stream5_IRQn);
  /* DMA1_Stream6_IRQn interrupt configuration */
  HAL_NVIC_SetPriority(DMA1_Stream6_IRQn, 5, 0);
  HAL_NVIC_EnableIRQ(DMA1_Stream6_IRQn);
  /* DMA2_Stream2_IRQn interrupt configuration */
  HAL_NVIC_SetPriority(DMA2_Stream2_IRQn, 5, 0);
  HAL_NVIC_EnableIRQ(DMA2_Stream2_IRQn);
  /* DMA2_Stream7_IRQn interrupt configuration */
  HAL_NVIC_SetPriority(DMA2_Stream7_IRQn, 5, 0);
  HAL_NVIC_EnableIRQ(DMA2_Stream7_IRQn);

}

static void MX_GPIO_Init(void)
{
  GPIO_InitTypeDef GPIO_InitStruct = {0};

  /* GPIO Ports Clock Enable */
  __HAL_RCC_GPIOC_CLK_ENABLE();
  __HAL_RCC_GPIOH_CLK_ENABLE();
  __HAL_RCC_GPIOA_CLK_ENABLE();
  __HAL_RCC_GPIOB_CLK_ENABLE();

  /*Configure GPIO pin Output Level */
  HAL_GPIO_WritePin(GPIOC, SENSORS_PWR_Pin|GPIO__12V_1_Pin|GPIO__5V_1_Pin|TXRX6_Pin
                          |DHT22_3_Pin|DHT22_2_Pin, GPIO_PIN_RESET);

  /*Configure GPIO pin Output Level */
  HAL_GPIO_WritePin(GPIOA, GPIO__12V_2_Pin|TXRX2_Pin|CAM_ON_Pin, GPIO_PIN_RESET);

  /*Configure GPIO pin Output Level */
  HAL_GPIO_WritePin(GPIOB, FAN_2_Pin|FAN_Pin|GPIO__12V_3_Pin|RASP_KEY_Pin
                          |DHT22_1_Pin|ALT_KEY_Pin, GPIO_PIN_RESET);

  /*Configure GPIO pin Output Level */
  HAL_GPIO_WritePin(CS2_GPIO_Port, CS2_Pin, GPIO_PIN_SET);

  /*Configure GPIO pin Output Level */
  HAL_GPIO_WritePin(GPIOA, GPIO3_RASP_Pin|CS1_Pin, GPIO_PIN_SET);

  /*Configure GPIO pins : SENSORS_PWR_Pin GPIO__12V_1_Pin GPIO__5V_1_Pin TXRX6_Pin
                           DHT22_3_Pin DHT22_2_Pin */
  GPIO_InitStruct.Pin = SENSORS_PWR_Pin|GPIO__12V_1_Pin|GPIO__5V_1_Pin|TXRX6_Pin
                          |DHT22_3_Pin|DHT22_2_Pin;
  GPIO_InitStruct.Mode = GPIO_MODE_OUTPUT_PP;
  GPIO_InitStruct.Pull = GPIO_NOPULL;
  GPIO_InitStruct.Speed = GPIO_SPEED_FREQ_LOW;
  HAL_GPIO_Init(GPIOC, &GPIO_InitStruct);

  /*Configure GPIO pin : MCPINT_Pin */
  GPIO_InitStruct.Pin = MCPINT_Pin;
  GPIO_InitStruct.Mode = GPIO_MODE_IT_FALLING;
  GPIO_InitStruct.Pull = GPIO_PULLUP;
  HAL_GPIO_Init(MCPINT_GPIO_Port, &GPIO_InitStruct);

  /*Configure GPIO pins : WKUP_Pin GPIO17_Pin */
  GPIO_InitStruct.Pin = WKUP_Pin|GPIO17_Pin;
  GPIO_InitStruct.Mode = GPIO_MODE_INPUT;
  GPIO_InitStruct.Pull = GPIO_NOPULL;
  HAL_GPIO_Init(GPIOA, &GPIO_InitStruct);

  /*Configure GPIO pins : GPIO__12V_2_Pin TXRX2_Pin CAM_ON_Pin GPIO3_RASP_Pin */
  GPIO_InitStruct.Pin = GPIO__12V_2_Pin|TXRX2_Pin|CAM_ON_Pin|GPIO3_RASP_Pin;
  GPIO_InitStruct.Mode = GPIO_MODE_OUTPUT_PP;
  GPIO_InitStruct.Pull = GPIO_NOPULL;
  GPIO_InitStruct.Speed = GPIO_SPEED_FREQ_LOW;
  HAL_GPIO_Init(GPIOA, &GPIO_InitStruct);

  /*Configure GPIO pin : ADXL2_INT_Pin */
  GPIO_InitStruct.Pin = ADXL2_INT_Pin;
  GPIO_InitStruct.Mode = GPIO_MODE_IT_RISING;
  GPIO_InitStruct.Pull = GPIO_NOPULL;
  HAL_GPIO_Init(ADXL2_INT_GPIO_Port, &GPIO_InitStruct);

  /*Configure GPIO pins : FAN_2_Pin FAN_Pin GPIO__12V_3_Pin RASP_KEY_Pin
                           DHT22_1_Pin ALT_KEY_Pin */
  GPIO_InitStruct.Pin = FAN_2_Pin|FAN_Pin|GPIO__12V_3_Pin|RASP_KEY_Pin
                          |DHT22_1_Pin|ALT_KEY_Pin;
  GPIO_InitStruct.Mode = GPIO_MODE_OUTPUT_PP;
  GPIO_InitStruct.Pull = GPIO_NOPULL;
  GPIO_InitStruct.Speed = GPIO_SPEED_FREQ_LOW;
  HAL_GPIO_Init(GPIOB, &GPIO_InitStruct);

  /*Configure GPIO pin : CS2_Pin */
  GPIO_InitStruct.Pin = CS2_Pin;
  GPIO_InitStruct.Mode = GPIO_MODE_OUTPUT_PP;
  GPIO_InitStruct.Pull = GPIO_NOPULL;
  GPIO_InitStruct.Speed = GPIO_SPEED_FREQ_VERY_HIGH;
  HAL_GPIO_Init(CS2_GPIO_Port, &GPIO_InitStruct);

  /*Configure GPIO pin : CS1_Pin */
  GPIO_InitStruct.Pin = CS1_Pin;
  GPIO_InitStruct.Mode = GPIO_MODE_OUTPUT_PP;
  GPIO_InitStruct.Pull = GPIO_NOPULL;
  GPIO_InitStruct.Speed = GPIO_SPEED_FREQ_VERY_HIGH;
  HAL_GPIO_Init(CS1_GPIO_Port, &GPIO_InitStruct);

  /*Configure GPIO pin : GERCON_Pin */
  GPIO_InitStruct.Pin = GERCON_Pin;
  GPIO_InitStruct.Mode = GPIO_MODE_INPUT;
  GPIO_InitStruct.Pull = GPIO_NOPULL;
  HAL_GPIO_Init(GERCON_GPIO_Port, &GPIO_InitStruct);

  /* EXTI interrupt init*/
  HAL_NVIC_SetPriority(EXTI1_IRQn, 5, 0);
  HAL_NVIC_EnableIRQ(EXTI1_IRQn);

  HAL_NVIC_SetPriority(EXTI4_IRQn, 5, 0);
  HAL_NVIC_EnableIRQ(EXTI4_IRQn);

}

/* USER CODE BEGIN 4 */

void configureTimerForRunTimeStats(void)
{
	ulHighFrequencyTimerTicks = 0;
	HAL_TIM_Base_Start_IT(&htim14);
}

unsigned long getRunTimeCounterValue(void)
{
return ulHighFrequencyTimerTicks;
}

void setStatusBytes (void) {

	if (HAL_GPIO_ReadPin(SENSORS_PWR_GPIO_Port, SENSORS_PWR_Pin) == GPIO_PIN_SET){
		misStatusByte0 |= 0x01;
	} else {
		misStatusByte0 &= ~0x01;
	}
	if (HAL_GPIO_ReadPin(ALT_KEY_GPIO_Port, ALT_KEY_Pin) == GPIO_PIN_SET){
		misStatusByte0 |= 0x02;
	} else {
		misStatusByte0 &= ~0x02;
	}
	if (HAL_GPIO_ReadPin(GPIO__12V_1_GPIO_Port, GPIO__12V_1_Pin) == GPIO_PIN_SET){
		misStatusByte0 |= 0x04;
	} else {
		misStatusByte0 &= ~0x04;
	}
	if (HAL_GPIO_ReadPin(GPIO__12V_2_GPIO_Port, GPIO__12V_2_Pin) == GPIO_PIN_SET){
		misStatusByte0 |= 0x08;
	} else {
		misStatusByte0 &= ~0x08;
	}
	if (HAL_GPIO_ReadPin(GPIO__12V_3_GPIO_Port, GPIO__12V_3_Pin) == GPIO_PIN_SET){
		misStatusByte0 |= 0x10;
	} else {
		misStatusByte0 &= ~0x10;
	}
	if (HAL_GPIO_ReadPin(FAN_GPIO_Port, FAN_Pin) == GPIO_PIN_SET){
		misStatusByte0 |= 0x20;
	} else {
		misStatusByte0 &= ~0x20;
	}
	if (HAL_GPIO_ReadPin(FAN_2_GPIO_Port, FAN_2_Pin) == GPIO_PIN_SET){
		misStatusByte0 |= 0x40;
	} else {
		misStatusByte0 &= ~0x40;
	}
	if (HAL_GPIO_ReadPin(GPIO__5V_1_GPIO_Port, GPIO__5V_1_Pin) == GPIO_PIN_SET){
		misStatusByte0 |= 0x80;
	} else {
		misStatusByte0 &= ~0x80;
	}
	if (HAL_GPIO_ReadPin(CAM_ON_GPIO_Port, CAM_ON_Pin) == GPIO_PIN_SET){
		misStatusByte1 |= 0x01;
	} else {
		misStatusByte1 &= ~0x01;
	}
}

void allConsumersEnable(void) {

	HAL_GPIO_WritePin(RASP_KEY_GPIO_Port, RASP_KEY_Pin, SET);
	HAL_GPIO_WritePin(ALT_KEY_GPIO_Port, ALT_KEY_Pin, SET);
	HAL_GPIO_WritePin(GPIO__12V_1_GPIO_Port, GPIO__12V_1_Pin, SET);
	HAL_GPIO_WritePin(GPIO__12V_2_GPIO_Port, GPIO__12V_2_Pin, SET);
	HAL_GPIO_WritePin(GPIO__12V_3_GPIO_Port, GPIO__12V_3_Pin, SET);
	HAL_GPIO_WritePin(FAN_2_GPIO_Port, FAN_2_Pin, SET);
//	HAL_GPIO_WritePin(GPIO__5V_1_GPIO_Port, GPIO__5V_1_Pin, SET);
	HAL_GPIO_WritePin(CAM_ON_GPIO_Port, CAM_ON_Pin, SET);
}

void allConsumersDisable(void) {
	HAL_GPIO_WritePin(GPIO__12V_1_GPIO_Port, GPIO__12V_1_Pin, RESET);
	HAL_GPIO_WritePin(GPIO__12V_2_GPIO_Port, GPIO__12V_2_Pin, RESET);
	HAL_GPIO_WritePin(FAN_GPIO_Port, FAN_Pin, RESET);
	HAL_GPIO_WritePin(FAN_2_GPIO_Port, FAN_2_Pin, RESET);
//	HAL_GPIO_WritePin(GPIO__5V_1_GPIO_Port, GPIO__5V_1_Pin, RESET);
}

void setTxMode (uint8_t uartNo){
	switch (uartNo){
	case 2:
		HAL_GPIO_WritePin(TXRX2_GPIO_Port, TXRX2_Pin, SET);
		break;
	case 6:
		HAL_GPIO_WritePin(TXRX6_GPIO_Port, TXRX6_Pin, SET);
		break;
	}
}

void setRxMode (uint8_t uartNo){
	switch (uartNo){
	case 2:
		HAL_GPIO_WritePin(TXRX2_GPIO_Port, TXRX2_Pin, RESET);
		break;
	case 6:
		HAL_GPIO_WritePin(TXRX6_GPIO_Port, TXRX6_Pin, RESET);
		break;
	default:
		break;
	}

}

void HAL_UART_TxCpltCallback(UART_HandleTypeDef *huart){

	if (huart->Instance == USART2) {
		setRxMode(2);
	}
	if (huart->Instance == USART6) {
		setRxMode(6);
		if (resetFlag) {
			resetFlag = 0;
			NVIC_SystemReset();
		}
	}
}

void HAL_GPIO_EXTI_Callback(uint16_t GPIO_Pin) {

	if (GPIO_Pin == GPIO_PIN_4) {
		osSignalSet(accelHandle, 0x01);
	}
	if (GPIO_Pin == GPIO_PIN_1) {
		osSignalSet (canRxHandle, 0x0A);
	}

}

void HAL_UART_ErrorCallback(UART_HandleTypeDef *huart)
{
	if ((__HAL_UART_GET_FLAG(huart, UART_FLAG_ORE) != RESET) ||
			(__HAL_UART_GET_FLAG(huart, UART_FLAG_FE) != RESET) ||
					(__HAL_UART_GET_FLAG(huart, UART_FLAG_NE) != RESET)){
		huart->Instance->DR;
	}
	++uartErrorCounter;
	if (huart->Instance == USART1){
		HAL_UART_AbortReceive(&huart1);
		HAL_UART_AbortTransmit(&huart1);
		HAL_UART_Receive_DMA(&huart1, raspRxBuf, RASP_RX_BUF_SIZE);
	} else if (huart->Instance == USART6){
		HAL_UART_AbortReceive_IT(huart);
		HAL_UART_AbortTransmit_IT(huart);
		HAL_UARTEx_ReceiveToIdle_IT(&huart6, currentVoltageRxBuf, CV_RX_BUF_SIZE);
	}
}

void HAL_I2C_ErrorCallback(I2C_HandleTypeDef *hi2c)
{
	i2c2ErrorCode = HAL_I2C_GetError(&hi2c2);
}
/* USER CODE END 4 */

void StartDefaultTask(void const * argument)
{
  /* USER CODE BEGIN 5 */
	osEvent event1;

	__HAL_UART_ENABLE_IT(&huart1, UART_IT_IDLE);
	HAL_UART_Receive_DMA(&huart1, raspRxBuf, RASP_RX_BUF_SIZE);
	HAL_UARTEx_ReceiveToIdle_IT(&huart6, currentVoltageRxBuf, CV_RX_BUF_SIZE);

	/* Infinite loop */
	for (;;) {

		event1 = osMessageGet(onOffQueueHandle, osWaitForever);
		if (event1.status == osEventMessage){
			switch (event1.value.v) {

			case ENGINE_START_ID:

				allConsumersEnable();
				break;

			case ENGINE_STOP_ID:

				allConsumersDisable();
				osDelay(20000);
				HAL_GPIO_WritePin(RASP_KEY_GPIO_Port, RASP_KEY_Pin, RESET);
				break;
			}
		}
	}
  /* USER CODE END 5 */
}

__weak void lightMeterTask(void const * argument)
{
}

void accelTask(void const * argument)
{
  /* USER CODE BEGIN accelTask */

	osEvent evt;
	uint8_t buffer[6];
	sensorsData xSensors;
	sensorsData *sensors = &xSensors;
	HAL_I2C_Init(&hi2c2);
	ADXL345_Init();

	/* Infinite loop */
	for (;;) {
		evt = osSignalWait(0x01, osWaitForever);
		if (evt.status == osEventSignal) {
			if (osMutexWait(I2C2MutexHandle, 5) == osOK){
				intSource = getInterruptSource();
				ADXL345_Read(buffer);
				osMutexRelease(I2C2MutexHandle);
			}
			accelX =(int16_t) buffer[1] << 8;
			accelX |=(int16_t) buffer[0];
			Xresult = (float)accelX * 0.0156;
			accelY = (int16_t) buffer[3] << 8;
			accelY |= (int16_t)buffer[2];
			Yresult = (float)accelY * 0.0156;
			accelZ = (int16_t)buffer[5] << 8;
			accelZ |= (int16_t)buffer[4];
			Zresult = (float)accelZ * 0.0156;
			HAL_TIM_PWM_Start(&htim3, TIM_CHANNEL_1);
			osDelay(200);
			HAL_TIM_PWM_Stop(&htim3, TIM_CHANNEL_1);
			sensors->source = ADXL_TASK;
			sensors->size = ADXL_SIZE;
			memcpy (sensors->payload, buffer, 6);
			if (xQueueSend(qSensorsHandle, (void*) &sensors, 1) != pdTRUE) {
			}
		}
	}
  /* USER CODE END accelTask */
}

void tempMeasTask(void const * argument)
{
  /* USER CODE BEGIN tempMeasTask */
	static uint8_t buffer0[2] = {0};
	static uint8_t buffer2[2] = {0};

	int16_t temperature0 = 0;
	int16_t temperature2 = 0;
	static uint8_t fanState = 0;
	osStatus tempMutexStatus0;

	sensorsData xSensors;
	sensorsData *sensors = &xSensors;

	osDelay(500);
	__HAL_I2C_ENABLE_IT(&hi2c2, I2C_IT_ERR);
	/* Infinite loop */
	for (;;) {

		tempMutexStatus0 = osMutexWait(I2C2MutexHandle, 1);

		if (tempMutexStatus0 == osOK) {
			tempSensorState = TLA2024_Read(0, buffer0);
			tempSensorState1 = TLA2024_Read(2, buffer2);
			osMutexRelease(I2C2MutexHandle);
		}

		temperature0 = (int16_t)buffer0[0] << 8;
		temperature0 |= buffer0[1];
		temperature2 = (int16_t)buffer2[0] << 8;
		temperature2 |= buffer2[1];

		debugTemp0 = temperature0;
		debugTemp2 = temperature2;

		if (temperature0 < 0) {
			temperature0 = -temperature0;
			temperature0 |= 0x8000;
		}

		if (temperature2 < 0) {
			temperature2 = -temperature2;
			temperature2 |= 0x8000;
		}

		buffer0[0] = (uint8_t)((temperature0 & 0xFF00) >> 8);
		buffer0[1] = (uint8_t)(temperature0 & 0x00FF);
		buffer2[0] = (uint8_t)((temperature2 & 0xFF00) >> 8);
		buffer2[1] = (uint8_t)(temperature2 & 0x00FF);

		if (tempSensorState == TEMP_SENSOR_FAIL) {
			queueStatusByte1 |= 0x01;
		} else {
			queueStatusByte1 &= ~0x01;
		}

		if (tempSensorState1 == TEMP_SENSOR_FAIL) {
			queueStatusByte1 |= 0x02;
		} else {
			queueStatusByte1 &= ~0x02;
		}

		if ((tempSensorState == TEMP_SENSOR_FAIL) && (cvStatusByteExtern & 0x06)) {

			HAL_GPIO_WritePin(FAN_GPIO_Port, FAN_Pin, SET);

		} else {
			switch (fanState) {
			case 0:
				if (temperature0 > TEMPERATURE) {
					HAL_GPIO_WritePin(FAN_GPIO_Port, FAN_Pin, SET);
					fanState++;
				}
				break;
			case 1:
				if (temperature0 < (TEMPERATURE-TEMP_HYSTERESE)){
					HAL_GPIO_WritePin(FAN_GPIO_Port, FAN_Pin, RESET);
					fanState = 0;
				}
				break;
			}
		}

		if (!tempSensorState && !tempSensorState1) {
			if (hi2c2.ErrorCode){
				HAL_I2C_DeInit(&hi2c2);
				__HAL_RCC_I2C2_FORCE_RESET();
				osDelay(10);
				__HAL_RCC_I2C2_RELEASE_RESET();
				HAL_I2C_Init(&hi2c2);
			}
		} else {
			sensors->source = TLA2024_TASK_SOURCE;
			sensors->size = TLA2024_SIZE;
			memset(sensors->payload, 0, 16);
			memcpy (sensors->payload, buffer0, 2);
			memcpy (sensors->payload+4, buffer2, 2);
			if (xQueueSend(qSensorsHandle, (void*) &sensors, 5) != pdTRUE) {

			}

			if (sensorsOnFlag) {
				HAL_GPIO_WritePin(SENSORS_PWR_GPIO_Port, SENSORS_PWR_Pin, SET);
			} else {
				HAL_GPIO_WritePin(SENSORS_PWR_GPIO_Port, SENSORS_PWR_Pin, RESET);
			}

			osDelay(500);
		}
	}
  /* USER CODE END tempMeasTask */
}

__weak void uartCommTask(void const * argument)
{
}

void HAL_TIM_PeriodElapsedCallback(TIM_HandleTypeDef *htim)
{
  /* USER CODE BEGIN Callback 0 */

	BaseType_t xHigherPriorityTaskWoken = (BaseType_t) 0;

	uint8_t request[6] = { PACKET_HEADER, CV_REQ_PACK_ID, CV_REQ_SIZE,
			CMD_CV_REQUEST, 0, PACKET_FOOTER };
	request[4] = get_check_sum(request, 6);

	if (htim->Instance == TIM11) {

		if (tickCounter < 1000) {
			tickCounter++;
		} else {
			tickCounter = 0;
			osSignalSet(uartCommHandle, 0x02);
			HAL_GPIO_TogglePin(GPIO__5V_1_GPIO_Port, GPIO__5V_1_Pin);
		}

/*------------------------------------------------------------------------------------------*/

		if (cvRequestCounter < 500) {
			cvRequestCounter++;

		} else {
			cvRequestCounter = 0;
			sensor->source = CV_REQ_SOURCE;
			sensor->size = CV_REQ_SIZE;
			memcpy((uint8_t*)sensor->payload, request, CV_REQ_SIZE);
			if (xQueueSendFromISR(qSensorsHandle, (void *)&sensor, &xHigherPriorityTaskWoken) != pdTRUE){
			}
			portEND_SWITCHING_ISR(xHigherPriorityTaskWoken);

			if (engineState == ENGINE_STOPPED)  {
				if (!breaksStateTelem){
					secondCounter++;
				} else {
					secondCounter = 0;
				}
			} else {
				secondCounter = 0;
			}
		}

/*------------------------------------------------------------------------------------------*/

		if (secondCounter >= 120){
			secondCounter = 0;
			if (engineState == ENGINE_STOPPED)  {
				HAL_GPIO_WritePin(ALT_KEY_GPIO_Port, ALT_KEY_Pin, RESET);
				HAL_GPIO_WritePin(GPIO__12V_3_GPIO_Port, GPIO__12V_3_Pin, RESET);
			}
		}

/*------------------------------------------------------------------------------------------*/

	switch (raspOffState) {

	case 0:
		if ((gpio17State = HAL_GPIO_ReadPin(GPIO17_GPIO_Port, GPIO17_Pin)) == GPIO_PIN_SET){
			if (raspOffCounter < 20){
				raspOffCounter++;
			} else {
				raspOffCounter = 0;
				raspOffState++;
			}
		} else {
			if (timeOutFlag) {
				if ((HAL_GetTick() - timeoutCnt) >= TIMEOUT_GPIO17) {
					timeOutFlag = 0;
					raspRestartFlag = 1;
				}
			}
			raspOffCounter = 0;
		}
		break;

	case 1:
		if ((gpio17State = HAL_GPIO_ReadPin(GPIO17_GPIO_Port, GPIO17_Pin)) == GPIO_PIN_RESET) {

			if (raspOffCounter < 5) {
				raspOffCounter++;
			} else {
				raspOffCounter = 0;
				sensor->source = RASP_UART_SRC;
				sensor->size = CV_REQ_SIZE;
				sensor->payload[0] = 0xAA;
				sensor->payload[1] = RASP_IN_PACK_ID;
				sensor->payload[2] = CV_REQ_SIZE;
				sensor->payload[3] = CMD_BACKLIGHT_OFF;
				sensor->payload[4] = get_check_sum((uint8_t*)(sensor->payload), CV_REQ_SIZE);
				sensor->payload[5] = 0x55;
				if (xQueueSendFromISR(qSensorsHandle, (void *) &sensor, &xHigherPriorityTaskWoken) != pdTRUE) {
				}
				portEND_SWITCHING_ISR(xHigherPriorityTaskWoken);
				if (breaksStateTelem) {
					turnOffBreaksFlag = 1;
					raspOffState = 3;
				} else {
					turnOffBreaksFlag = 0;
					raspOffState++;
				}
			}
		} else {
			raspOffCounter = 0;
		}
		break;

	case 2:
		if ((gpio17State = HAL_GPIO_ReadPin(GPIO17_GPIO_Port, GPIO17_Pin)) == GPIO_PIN_RESET) {
			stateChangeCounter = 0;
			if (raspOffCounter < 119950) {
				if (!breaksStateTelem){
					raspOffCounter++;
				} else {
					raspOffCounter = 0;
				}
			} else {
				raspOffCounter = 0;
				sensor->source = RASP_UART_SRC;
				sensor->size = CV_REQ_SIZE;
				sensor->payload[0] = 0xAA;
				sensor->payload[1] = RASP_IN_PACK_ID;
				sensor->payload[2] = CV_REQ_SIZE;
				sensor->payload[3] = CMD_PWR_OFF;
				sensor->payload[4] = get_check_sum((uint8_t*)sensor->payload, CV_REQ_SIZE);
				sensor->payload[5] = 0x55;
				allConsumersDisable();
				if (xQueueSendFromISR(qSensorsHandle, (void *)&sensor, &xHigherPriorityTaskWoken) != pdTRUE) {
				}
				portEND_SWITCHING_ISR(xHigherPriorityTaskWoken);
				HAL_GPIO_WritePin(RASP_KEY_GPIO_Port, RASP_KEY_Pin, RESET);
				raspOffState = 0;
			}
		} else {
			raspOffCounter = 0;
			if (stateChangeCounter < 300) {
				stateChangeCounter++;
			} else {
				stateChangeCounter = 0;
				raspOffState = 0;
			}
		}
		break;

	case 3:

		if ((gpio17State = HAL_GPIO_ReadPin(GPIO17_GPIO_Port, GPIO17_Pin)) == GPIO_PIN_RESET) {
			if (raspOffCounter < 119950) {
					raspOffCounter++;
			} else {
				raspOffCounter = 0;
				sensor->source = RASP_UART_SRC;
				sensor->size = CV_REQ_SIZE;
				sensor->payload[0] = 0xAA;
				sensor->payload[1] = RASP_IN_PACK_ID;
				sensor->payload[2] = CV_REQ_SIZE;
				sensor->payload[3] = CMD_PWR_OFF;
				sensor->payload[4] = get_check_sum((uint8_t*)sensor->payload, CV_REQ_SIZE);
				sensor->payload[5] = 0x55;
				allConsumersDisable();
				if (xQueueSendFromISR(qSensorsHandle, (void *)&sensor, &xHigherPriorityTaskWoken) != pdTRUE) {
				}
				portEND_SWITCHING_ISR(xHigherPriorityTaskWoken);
				HAL_GPIO_WritePin(RASP_KEY_GPIO_Port, RASP_KEY_Pin, RESET);
				raspOffState = 0;
			}
		} else {
			raspOffCounter = 0;
			if (stateChangeCounter < 100) {
				stateChangeCounter++;
			} else {
				stateChangeCounter = 0;
				raspOffState = 0;
			}
		}
		break;
	}

/*------------------------------------------------------------------------------------------*/

	  switch (gerconState){
	  case 0:
		  if (!HAL_GPIO_ReadPin(GERCON_GPIO_Port, GERCON_Pin)){
			  if (gerconCounter < 50){
 				  gerconCounter++;
			  } else {
				  gerconCounter = 0;
				  gerconState++;
			  }
		  } else {
			  gerconCounter = 0;
		  }
		  break;
	  case 1:
		  if (HAL_GPIO_ReadPin(GERCON_GPIO_Port, GERCON_Pin)){
			  if (gerconCounter < 500){
				  gerconCounter++;
			  } else {
				  gerconCounter = 0;
				  gerconState = 0;
			  }
		  } else {
			  gerconCounter = 0;
		  }
		  break;
	  }

/*------------------------------------------------------------------------------------------*/

	  if (HAL_GPIO_ReadPin(WKUP_GPIO_Port, WKUP_Pin) == GPIO_PIN_SET) {
		  if (wakeUpPinCounter < 100) {
			  wakeUpPinCounter++;
		  } else {
			  wakeUpPinCounter = 0;
			  wakeUpFlag = 1;
		  }
	  } else {
		  wakeUpPinCounter = 0;
	  }

	}

/*------------------------------------------------------------------------------------------*/

	if (htim->Instance == TIM13) { //Таймаут команды управления SourceSelector
		HAL_TIM_Base_Stop_IT(&htim13);
		__HAL_TIM_CLEAR_IT(&htim13, TIM_IT_UPDATE);
		sensor1->source = CV_RESP_SOURCE;
		sensor1->size = RASP_RESP_SIZE;
		sensor1->payload[6] = get_check_sum((uint8_t*)sensor1->payload, 8);
		memcpy((uint8_t*)sensor1->payload, cvTimeoutResponse, 8);
		sensor1->payload[3] = cmdTempBuf[3];
		if (xQueueSendFromISR(qSensorsHandle, (void *)&sensor1, &xHigherPriorityTaskWoken) != pdTRUE) {
		}
		portEND_SWITCHING_ISR(xHigherPriorityTaskWoken);
	}

	/*------------------------------------------------------------------------------------------*/

	if (htim->Instance == TIM8) { //Сюда мы попадаем, если 200ms нет ответа от SourceSelector
		HAL_TIM_Base_Stop_IT(&htim8);
		++timeOutCounter;
		if (timeOutCounter >= 10){
			timeOutCounter = 0;
			HAL_UART_AbortReceive_IT(&huart6);
			HAL_UART_AbortTransmit_IT(&huart6);
			HAL_UART_DeInit(&huart6);
			MX_USART6_UART_Init();
			HAL_UARTEx_ReceiveToIdle_IT(&huart6, currentVoltageRxBuf, CV_RX_BUF_SIZE);
		}
		__HAL_TIM_SET_COUNTER(&htim8, 0);
		for (cvCounter = 0; cvCounter < CV_RX_BUF_SIZE; cvCounter++) {
			currentVoltageRxBuf[cvCounter] = 0;
		}
		queueStatusByte1 |= 0x80;
	}

  /* USER CODE END Callback 0 */
  if (htim->Instance == TIM6) {
    HAL_IncTick();
  }
}

void Error_Handler(void)
{
  __disable_irq();
  while (1)
  {
  }
}

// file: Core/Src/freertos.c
/* USER CODE BEGIN Header */
/**
  ******************************************************************************
  * File Name          : freertos.c
  * Description        : Code for freertos applications
  ******************************************************************************
  * @attention
  *
  * <h2><center>&copy; Copyright (c) 2021 STMicroelectronics.
  * All rights reserved.</center></h2>
  *
  * This software component is licensed by ST under Ultimate Liberty license
  * SLA0044, the "License"; You may not use this file except in compliance with
  * the License. You may obtain a copy of the License at:
  *                             www.st.com/SLA0044
  *
  ******************************************************************************
  */
/* USER CODE END Header */

#include "FreeRTOS.h"
#include "task.h"
#include "main.h"

/* GetIdleTaskMemory prototype (linked to static allocation support) */
void vApplicationGetIdleTaskMemory( StaticTask_t **ppxIdleTaskTCBBuffer, StackType_t **ppxIdleTaskStackBuffer, uint32_t *pulIdleTaskStackSize );

/* Hook prototypes */
void configureTimerForRunTimeStats(void);
unsigned long getRunTimeCounterValue(void);

/* USER CODE BEGIN 1 */
/* Functions needed when configGENERATE_RUN_TIME_STATS is on */
__weak void configureTimerForRunTimeStats(void)
{

}

__weak unsigned long getRunTimeCounterValue(void)
{
return 0;
}
/* USER CODE END 1 */

/* USER CODE BEGIN GET_IDLE_TASK_MEMORY */
static StaticTask_t xIdleTaskTCBBuffer;
static StackType_t xIdleStack[configMINIMAL_STACK_SIZE];

void vApplicationGetIdleTaskMemory( StaticTask_t **ppxIdleTaskTCBBuffer, StackType_t **ppxIdleTaskStackBuffer, uint32_t *pulIdleTaskStackSize )
{
  *ppxIdleTaskTCBBuffer = &xIdleTaskTCBBuffer;
  *ppxIdleTaskStackBuffer = &xIdleStack[0];
  *pulIdleTaskStackSize = configMINIMAL_STACK_SIZE;
  /* place for user code */
}
/* USER CODE END GET_IDLE_TASK_MEMORY */
